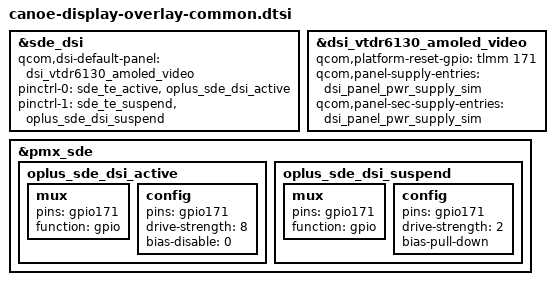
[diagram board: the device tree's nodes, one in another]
&sde_dsi {
	qcom,dsi-default-panel = <&dsi_vtdr6130_amoled_video>;
	pinctrl-names = "panel_active", "panel_suspend";
	pinctrl-0 = <&sde_te_active &oplus_sde_dsi_active>;
	pinctrl-1 = <&sde_te_suspend &oplus_sde_dsi_suspend>;
};

&dsi_vtdr6130_amoled_video {
	/delete-property/ qcom,esd-check-enabled;
	qcom,platform-reset-gpio = <&tlmm 171 0>;
	qcom,panel-supply-entries = <&dsi_panel_pwr_supply_sim>;
	qcom,panel-sec-supply-entries = <&dsi_panel_pwr_supply_sim>;
};

&pmx_sde {
	oplus_sde_dsi_active: oplus_sde_dsi_active {
		mux {
			pins = "gpio171";
			function = "gpio";
		};

		config {
			pins = "gpio171";
			drive-strength = <8>;   /* 8 mA */
			bias-disable = <0>;   /* no pull */
		};
	};

	oplus_sde_dsi_suspend: oplus_sde_dsi_suspend {
		mux {
			pins = "gpio171";
			function = "gpio";
		};

		config {
			pins = "gpio171";
			drive-strength = <2>;   /* 2 mA */
			bias-pull-down;         /* PULL DOWN */
		};
	};
};
